# ATmega16HVA device description
Architecture: AVR8; Family: megaAVR
Programming and debug interfaces: ISP, HVSP, debugWIRE
Registers are 8-bit, access not given, no defined reset value unless marked. A register's access mark holds for its fields unless they carry their own. Offsets are from the block's base; lines under a group give offsets from that group; [hi:lo] are bit positions; {n}, {i} and the like mark numbered series; 'fields as' and 'values as' point back to an identical list; <NAME> marks a mode.

## Ordering variants
standard: 1.8 to 4.5 V

## Memory
prog space: start 0x0000 size 0x4000, little endian
  0x0000 FLASH size 0x4000 flash, rw, executable, page 0x80
signatures space: start 0 size 3, little endian
  0 SIGNATURES size 3 signatures, ro
fuses space: start 0 size 0x0001, little endian
  0 FUSES size 0x0001 fuses, rw
lockbits space: start 0 size 0x0001, little endian
  0 LOCKBITS size 0x0001 lockbits, rw
data space: start 0x0000 size 0x0300, little endian
  0x0000 REGISTERS size 0x0020 regs
  0x0020 MAPPED_IO size 0x00e0 io
  0x0100 IRAM size 0x0200 ram
eeprom space: start 0x0000 size 0x0100, little endian
  0x0000 EEPROM size 0x0100 eeprom, rw, page 0x04
io space: start 0x00 size 0x40, little endian

## Peripheral instances (address, pins/pin function, parameters)
ADC at 0x00 — Analog-to-Digital Converter
WDT at 0x00 — Watchdog Timer
BANDGAP at 0x00
EXINT at 0x00 — External Interrupts
PORTC at 0x00 — I/O Port
PORTA at 0x00 — I/O Port
PORTB at 0x00 — I/O Port
FET at 0x00 — FET Control
SPI at 0x00 — Serial Peripheral Interface
BOOT_LOAD at 0x00 — Bootloader
CPU at 0x00 — CPU Registers
  parameters: CORE_VERSION=V2E
BATTERY_PROTECTION at 0x00
EEPROM at 0x00
TC1 at 0x00 — Timer/Counter, 16-bit
TC0 at 0x00 — Timer/Counter, 16-bit
COULOMB_COUNTER at 0x00
VOLTAGE_REGULATOR at 0x00
FUSE at 0 in fuses — Fuses
LOCKBIT at 0 in lockbits — Lockbits

## Interrupts
0 RESET — External Pin, Power-on Reset, Brown-out Reset and Watchdog Reset
1 BPINT — Battery Protection Interrupt
2 VREGMON — Voltage regulator monitor interrupt
3 INT0 — External Interrupt Request 0
4 INT1 — External Interrupt Request 1
5 INT2 — External Interrupt Request 2
6 WDT — Watchdog Timeout Interrupt
7 TIMER1_IC — Timer 1 Input capture
8 TIMER1_COMPA — Timer 1 Compare Match A
9 TIMER1_COMPB — Timer 1 Compare Match B
10 TIMER1_OVF — Timer 1 overflow
11 TIMER0_IC — Timer 0 Input Capture
12 TIMER0_COMPA — Timer 0 Comapre Match A
13 TIMER0_COMPB — Timer 0 Compare Match B
14 TIMER0_OVF — Timer 0 Overflow
15 SPI_STC — SPI Serial transfer complete
16 VADC — Voltage ADC Conversion Complete
17 CCADC_CONV — Coulomb Counter ADC Conversion Complete
18 CCADC_REG_CUR — Coloumb Counter ADC Regular Current
19 CCADC_ACC — Coloumb Counter ADC Accumulator
20 EE_READY — EEPROM Ready

## Properties
SIGNATURES: JTAGID=0x940C, SIGNATURE0=0x1e, SIGNATURE1=0x94, SIGNATURE2=0x0c
OCD: OCD_REVISION=1, OCD_DATAREG=0x31, PROGBASE=0x0000

## FUSE — Fuses
Instances: FUSE 0 in fuses
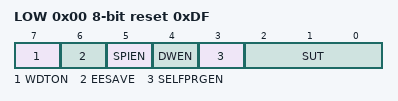
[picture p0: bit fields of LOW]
0x00 LOW reset 0xDF
  [7] WDTON — Watch-dog Timer always on
  [6] EESAVE — Preserve EEPROM through the Chip Erase cycle
  [5] SPIEN — Serial program downloading (SPI) enabled
  [4] DWEN — Debug Wire enable
  [3] SELFPRGEN — Self Programming enable
  [2:0] SUT — Select start-up time
    0=6CK_14CK_4MS (Start-up time 6 CK/14 CK + 4 ms); 1=6CK_14CK_8MS (Start-up time 6 CK/14 CK + 8 ms); 2=6CK_14CK_16MS (Start-up time 6 CK/14 CK + 16 ms); 3=6CK_14CK_32MS (Start-up time 6 CK/14 CK + 32 ms); 4=6CK_14CK_64MS (Start-up time 6 CK/14 CK + 64 ms); 5=6CK_14CK_128MS (Start-up time 6 CK/14 CK + 128 ms); 6=6CK_14CK_256MS (Start-up time 6 CK/14 CK + 256 ms); 7=6CK_14CK_512MS (Start-up time 6 CK/14 CK + 512 ms)

## LOCKBIT — Lockbits
Instances: LOCKBIT 0 in lockbits
0x00 LOCKBIT reset 0xFF
  [1:0] LB — Memory Lock
    0=PROG_VER_DISABLED (Further programming and verification disabled); 2=PROG_DISABLED (Further programming disabled); 3=NO_LOCK (No memory lock features enabled)

## ADC — Analog-to-Digital Converter
Instances: ADC 0x00
0x78 VADC 16-bit bits used 11:0 — VADC Data Register Bytes
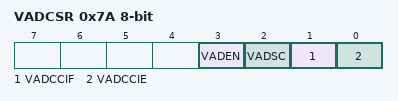
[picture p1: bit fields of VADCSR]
0x7A VADCSR — The VADC Control and Status register
  [3] VADEN — VADC Enable
  [2] VADSC — VADC Satrt Conversion
  [1] VADCCIF — VADC Conversion Complete Interrupt Flag
  [0] VADCCIE — VADC Conversion Complete Interrupt Enable
0x7C VADMUX — The VADC multiplexer Selection Register
  [3:0] VADMUX — Analog Channel and Gain Selection Bits
